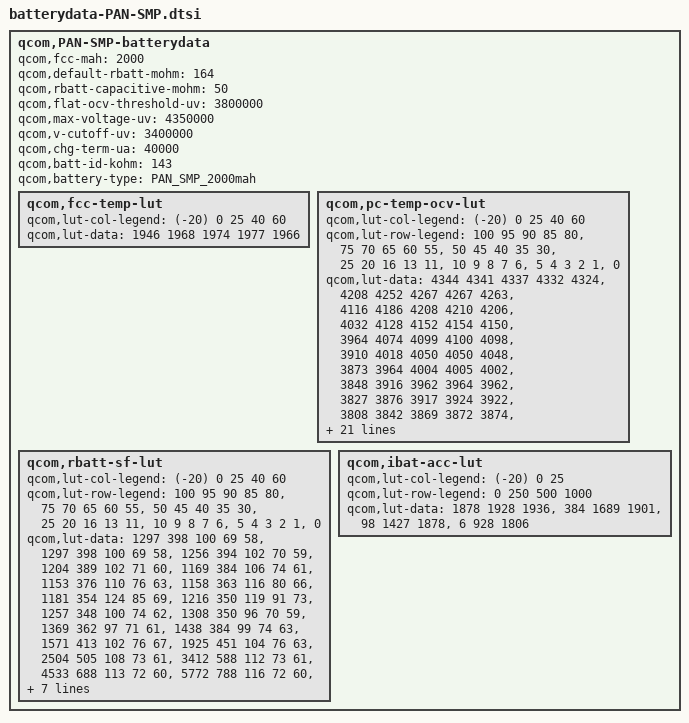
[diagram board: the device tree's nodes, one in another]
/* Copyright (c) 2013-2014, The Linux Foundation. All rights reserved.
 *
 * This program is free software; you can redistribute it and/or modify
 * it under the terms of the GNU General Public License version 2 and
 * only version 2 as published by the Free Software Foundation.
 *
 * This program is distributed in the hope that it will be useful,
 * but WITHOUT ANY WARRANTY; without even the implied warranty of
 * MERCHANTABILITY or FITNESS FOR A PARTICULAR PURPOSE.  See the
 * GNU General Public License for more details.
 */


qcom,PAN-SMP-batterydata {


	qcom,fcc-mah = <2000>;
	qcom,default-rbatt-mohm = <164>;
	qcom,rbatt-capacitive-mohm = <50>;
	qcom,flat-ocv-threshold-uv = <3800000>;
	qcom,max-voltage-uv = <4350000>;
	qcom,v-cutoff-uv = <3400000>;
	qcom,chg-term-ua = <40000>;
	qcom,batt-id-kohm = <143>;
	qcom,battery-type = "PAN_SMP_2000mah";

	qcom,fcc-temp-lut {
		qcom,lut-col-legend = <(-20) 0 25 40 60>;
		qcom,lut-data = <1946 1968 1974 1977 1966>;
	};

	qcom,pc-temp-ocv-lut {
		qcom,lut-col-legend = <(-20) 0 25 40 60>;
		qcom,lut-row-legend = <100 95 90 85 80>,
				<75 70 65 60 55>,
				<50 45 40 35 30>,
				<25 20 16 13 11>,
				<10 9 8 7 6>,
				<5 4 3 2 1>,
				<0>;
		qcom,lut-data = 
						<4344 4341 4337 4332 4324>, 
						<4208 4252 4267 4267 4263>, 
						<4116 4186 4208 4210 4206>, 
						<4032 4128 4152 4154 4150>, 
						<3964 4074 4099 4100 4098>, 
						<3910 4018 4050 4050 4048>, 
						<3873 3964 4004 4005 4002>, 
						<3848 3916 3962 3964 3962>, 
						<3827 3876 3917 3924 3922>, 
						<3808 3842 3869 3872 3874>, 
						<3790 3812 3838 3840 3842>, 
						<3772 3792 3814 3818 3818>, 
						<3753 3778 3796 3800 3800>, 
						<3734 3763 3780 3784 3784>, 
						<3712 3746 3768 3768 3761>, 
						<3689 3726 3754 3751 3739>, 
						<3661 3707 3732 3728 3715>, 
						<3632 3691 3702 3699 3686>, 
						<3606 3678 3685 3682 3670>, 
						<3582 3668 3678 3676 3666>, 
						<3570 3662 3675 3674 3666>, 
						<3555 3655 3674 3673 3664>, 
						<3540 3646 3670 3672 3662>, 
						<3522 3634 3666 3667 3654>, 
						<3500 3618 3654 3651 3630>, 
						<3471 3592 3624 3611 3586>, 
						<3433 3556 3572 3554 3528>, 
						<3378 3502 3503 3482 3452>, 
						<3294 3420 3408 3380 3343>, 
						<3178 3286 3252 3198 3190>, 
						<3000 3000 3000 3000 3000>;
	};

	qcom,rbatt-sf-lut {
		qcom,lut-col-legend = <(-20) 0 25 40 60>;
		qcom,lut-row-legend = <100 95 90 85 80>,
				<75 70 65 60 55>,
				<50 45 40 35 30>,
				<25 20 16 13 11>,
				<10 9 8 7 6>,
				<5 4 3 2 1>,
				<0>;
		qcom,lut-data =
						<1297 398 100 69 58>, 
						<1297 398 100 69 58>, 
						<1256 394 102 70 59>, 
						<1204 389 102 71 60>, 
						<1169 384 106 74 61>, 
						<1153 376 110 76 63>, 
						<1158 363 116 80 66>, 
						<1181 354 124 85 69>, 
						<1216 350 119 91 73>, 
						<1257 348 100 74 62>, 
						<1308 350 96 70 59>, 
						<1369 362 97 71 61>, 
						<1438 384 99 74 63>, 
						<1571 413 102 76 67>, 
						<1925 451 104 76 63>, 
						<2504 505 108 73 61>, 
						<3412 588 112 73 61>, 
						<4533 688 113 72 60>, 
						<5772 788 116 72 60>, 
						<6993 866 121 75 62>, 
						<7764 906 126 78 64>, 
						<8654 918 128 79 65>, 
						<9346 948 133 81 66>, 
						<10520 1020 142 84 66>, 
						<12716 1107 149 84 64>, 
						<15839 1218 151 81 63>, 
						<20640 1517 156 83 66>, 
						<28614 2228 175 92 73>, 
						<44389 3817 212 107 88>, 
						<84415 7635 319 166 175>, 
						<168830 15270 638 331 351>;
	};


	qcom,ibat-acc-lut {
		qcom,lut-col-legend = <(-20) 0 25>;
		qcom,lut-row-legend = <0 250 500 1000>;
		qcom,lut-data = 
				<1878 1928 1936>,
				<384 1689 1901>,
				<98 1427 1878>,
				<6 928 1806>;
	};


};
